# ATmega329P device description
Architecture: AVR8; Family: megaAVR
Registers are 8-bit, access not given, no defined reset value unless marked. A register's access mark holds for its fields unless they carry their own. Offsets are from the block's base; [hi:lo] are bit positions; {n}, {i} and the like mark numbered series.

## USI — Universal Serial Interface
Instances: USI 0x00
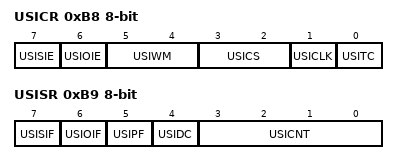
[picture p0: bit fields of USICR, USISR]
0xB8 USICR — USI Control Register
  [7] USISIE — Start Condition Interrupt Enable
  [6] USIOIE — Counter Overflow Interrupt Enable
  [5:4] USIWM — USI Wire Mode Bits
    0=Normal Operation; 1=Three-Wire Mode; 2=Two-Wire Mode; 3=Two-Wire Mode Held Low
  [3:2] USICS — USI Clock Source Select Bits
  [1] USICLK — Clock Strobe
  [0] USITC — Toggle Clock Port Pin
0xB9 USISR — USI Status Register
  [7] USISIF — Start Condition Interrupt Flag
  [6] USIOIF — Counter Overflow Interrupt Flag
  [5] USIPF — Stop Condition Flag
  [4] USIDC — Data Output Collision
  [3:0] USICNT — USI Counter Value Bits
0xBA USIDR — USI Data Register

## ADC — Analog-to-Digital Converter
Instances: ADC 0x00
0x78 ADC 16-bit — ADC Data Register Bytes
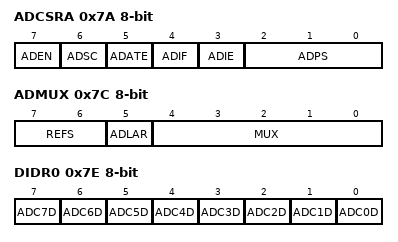
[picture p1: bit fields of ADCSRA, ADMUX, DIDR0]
0x7A ADCSRA — The ADC Control and Status register
  [7] ADEN — ADC Enable
  [6] ADSC — ADC Start Conversion
  [5] ADATE — ADC Auto Trigger Enable
  [4] ADIF — ADC Interrupt Flag
  [3] ADIE — ADC Interrupt Enable
  [2:0] ADPS — ADC Prescaler Select Bits
    0=2; 1=2; 2=4; 3=8; 4=16; 5=32; 6=64; 7=128
0x7B ADCSRB — ADC Control and Status Register B
  [2:0] ADTS — ADC Auto Trigger Sources
0x7C ADMUX — The ADC multiplexer Selection Register
  [7:6] REFS — Reference Selection Bits
    0=AREF, Internal Vref turned off; 1=AVCC with external capacitor at AREF pin; 3=Internal 1.1V Voltage Reference with external capacitor at AREF pin
  [5] ADLAR — Left Adjust Result
  [4:0] MUX — Analog Channel and Gain Selection Bits
0x7E DIDR0 — Digital Input Disable Register 0
  [n] ADC{n}D (n=0..7) — ADC{n} Digital input Disable

## BOOT_LOAD — Bootloader
Instances: BOOT_LOAD 0x00
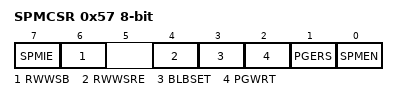
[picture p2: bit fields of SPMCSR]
0x57 SPMCSR — Store Program Memory Control Register
  [7] SPMIE — SPM Interrupt Enable
  [6] RWWSB — Read While Write Section Busy
  [4] RWWSRE — Read While Write section read enable
  [3] BLBSET — Boot Lock Bit Set
  [2] PGWRT — Page Write
  [1] PGERS — Page Erase
  [0] SPMEN — Store Program Memory Enable

## USART0 — USART
Instances: USART0 0x00
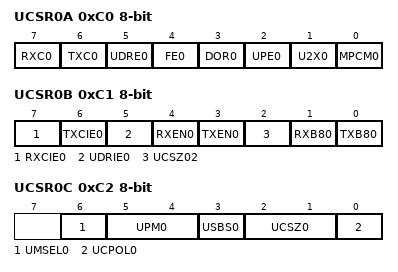
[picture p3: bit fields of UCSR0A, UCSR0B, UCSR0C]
0xC0 UCSR0A — USART Control and Status Register A
  [7] RXC0 — USART Receive Complete
  [6] TXC0 — USART Transmit Complete
  [5] UDRE0 — USART Data Register Empty
  [4] FE0 — Framing Error
  [3] DOR0 — Data OverRun
  [2] UPE0 — USART Parity Error
  [1] U2X0 — Double the USART Transmission Speed
  [0] MPCM0 — Multi-processor Communication Mode
0xC1 UCSR0B — USART Control and Status Register B
  [7] RXCIE0 — RX Complete Interrupt Enable
  [6] TXCIE0 — TX Complete Interrupt Enable
  [5] UDRIE0 — USART Data Register Empty Interrupt Enable
  [4] RXEN0 — Receiver Enable
  [3] TXEN0 — Transmitter Enable
  [2] UCSZ02 — Character Size
  [1] RXB80 — Receive Data Bit 8
  [0] TXB80 — Transmit Data Bit 8
0xC2 UCSR0C — USART Control and Status Register C
  [6] UMSEL0 — USART Mode Select
    0=Asynchronous Operation; 1=Synchronous Operation
  [5:4] UPM0 — Parity Mode Bits
    0=Disabled; 2=Enabled, Even Parity; 3=Enabled, Odd Parity
  [3] USBS0 — Stop Bit Select
    0=1-bit; 1=2-bit
  [2:1] UCSZ0 — Character Size
  [0] UCPOL0 — Clock Polarity
0xC4 UBRR0 16-bit bits used 11:0 — USART Baud Rate Register Bytes
0xC6 UDR0 — USART I/O Data Register

## LCD — Liquid Crystal Display
Instances: LCD 0x00
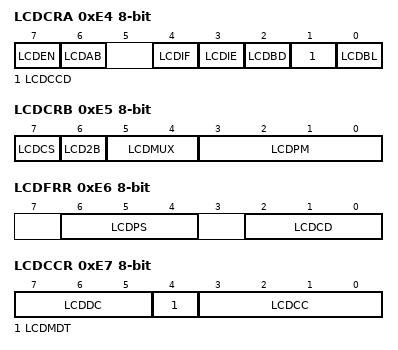
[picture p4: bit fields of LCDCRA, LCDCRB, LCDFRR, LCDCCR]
0xE4 LCDCRA — LCD Control Register A
  [7] LCDEN — LCD Enable
  [6] LCDAB — LCD A or B waveform
  [4] LCDIF — LCD Interrupt Flag
  [3] LCDIE — LCD Interrupt Enable
  [2] LCDBD — LCD Buffer Disable
  [1] LCDCCD — LCD Contrast Control Disable
  [0] LCDBL — LCD Blanking
0xE5 LCDCRB — LCD Control and Status Register B
  [7] LCDCS — LCD CLock Select
  [6] LCD2B — LCD 1/2 Bias Select
  [5:4] LCDMUX — LCD Mux Selects
  [3:0] LCDPM — LCD Port Masks
    0=SEG0:12; 1=SEG0:14; 2=SEG0:15; 3=SEG0:18; 4=SEG0:20; 5=SEG0:22; 6=SEG0:23; 7=SEG0:24; 8=SEG0:26; 9=SEG0:28; 10=SEG0:30; 11=SEG0:32; 12=SEG0:34; 13=SEG0:36; 14=SEG0:38; 15=SEG0:39
0xE6 LCDFRR — LCD Frame Rate Register
  [6:4] LCDPS — LCD Prescaler Selects
    0=ClkLCD/16; 1=ClkLCD/64; 2=ClkLCD/128; 3=ClkLCD/256; 4=ClkLCD/512; 5=ClkLCD/1024; 6=ClkLCD/2048; 7=ClkLCD/4096
  [2:0] LCDCD — LCD Clock Dividers
    {v}={v+1} (v=0..7)
0xE7 LCDCCR — LCD Contrast Control Register
  [7:5] LCDDC
    0=300us; 1=70us; 2=150us; 3=450us; 4=575us; 5=850us; 6=1150us; 7=50% of LCD clock
  [4] LCDMDT — LCD Maximum Drive Time
  [3:0] LCDCC — LCD Contrast Controls
    0=2.60V; 1=2.65V; 2=2.70V; 3=2.75V; 4=2.80V; 5=2.85V; 6=2.90V; 7=2.95V; 8=3.00V; 9=3.05V; 10=3.10V; 11=3.15V; 12=3.20V; 13=3.25V; 14=3.30V; 15=3.35V
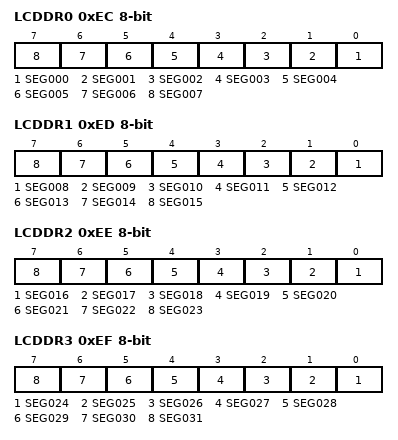
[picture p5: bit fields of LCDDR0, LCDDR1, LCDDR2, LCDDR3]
0xEC LCDDR0 — LCD Data Register 0
  [n] SEG{n:03} (n=0..7) — LCD memory bit segment
0xED LCDDR1 — LCD Data Register 1
  [n-8] SEG{n:03} (n=8..15) — LCD memory bit segment
0xEE LCDDR2 — LCD Data Register 2
  [n-16] SEG{n:03} (n=16..23) — LCD memory bit segment
0xEF LCDDR3 — LCD Data Register 3
  [n-24] SEG{n:03} (n=24..31) — LCD memory bit segment
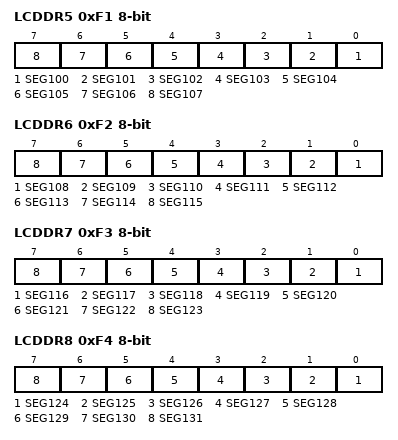
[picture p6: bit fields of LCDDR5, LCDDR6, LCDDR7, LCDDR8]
0xF1 LCDDR5 — LCD Data Register 5
  [n-100] SEG{n} (n=100..107) — LCD memory bit segment
0xF2 LCDDR6 — LCD Data Register 6
  [n-108] SEG{n} (n=108..115) — LCD memory bit segment
0xF3 LCDDR7 — LCD Data Register 7
  [n-116] SEG{n} (n=116..123) — LCD memory bit segment
0xF4 LCDDR8 — LCD Data Register 8
  [n-124] SEG{n} (n=124..131) — LCD memory bit segment
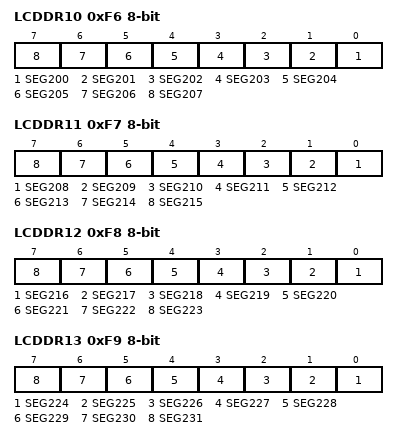
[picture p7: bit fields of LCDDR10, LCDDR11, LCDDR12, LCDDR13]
0xF6 LCDDR10 — LCD Data Register 10
  [n-200] SEG{n} (n=200..207) — LCD memory bit segment
0xF7 LCDDR11 — LCD Data Register 11
  [n-208] SEG{n} (n=208..215) — LCD memory bit segment
0xF8 LCDDR12 — LCD Data Register 12
  [n-216] SEG{n} (n=216..223) — LCD memory bit segment
0xF9 LCDDR13 — LCD Data Register 13
  [n-224] SEG{n} (n=224..231) — LCD memory bit segment
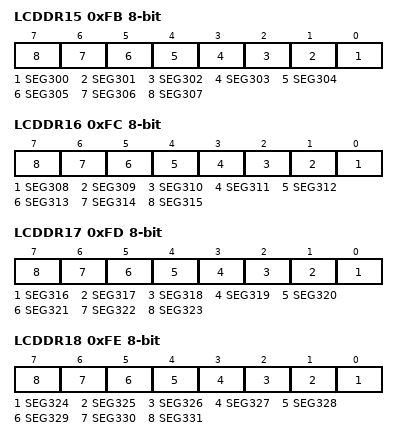
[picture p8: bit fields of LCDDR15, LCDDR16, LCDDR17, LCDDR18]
0xFB LCDDR15 — LCD Data Register 15
  [n-300] SEG{n} (n=300..307) — LCD memory bit segment
0xFC LCDDR16 — LCD Data Register 16
  [n-308] SEG{n} (n=308..315) — LCD memory bit segment
0xFD LCDDR17 — LCD Data Register 17
  [n-316] SEG{n} (n=316..323) — LCD memory bit segment
0xFE LCDDR18 — LCD Data Register 18
  [n-324] SEG{n} (n=324..331) — LCD memory bit segment

## CPU — CPU Registers
Instances: CPU 0x00
Parameters: CORE_VERSION=V2E
0x3E GPIOR0 — General Purpose IO Register 0
0x4A GPIOR1 — General Purpose IO Register 1
0x4B GPIOR2 — General Purpose IO Register 2
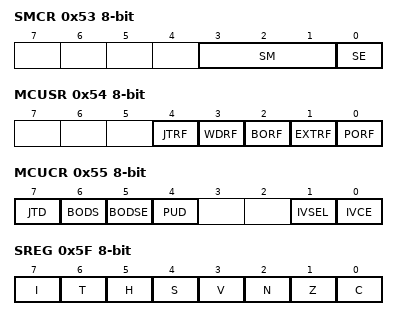
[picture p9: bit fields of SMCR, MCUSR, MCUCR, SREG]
0x53 SMCR — Sleep Mode Control Register
  [3:1] SM — Sleep Mode Select bits
    0=IDLE; 1=ADC (ADC Noise Reduction (If Available)); 2=PDOWN (Power Down); 3=PSAVE (Power Save); 6=STDBY (Standby)
  [0] SE — Sleep Enable
0x54 MCUSR — MCU Status Register
  [4] JTRF — JTAG Reset Flag
  [3] WDRF — Watchdog Reset Flag
  [2] BORF — Brown-out Reset Flag
  [1] EXTRF — External Reset Flag
  [0] PORF — Power-on reset flag
0x55 MCUCR — MCU Control Register
  [7] JTD — JTAG Interface Disable
  [6] BODS — BOD Sleep
  [5] BODSE — BOD Sleep Enable
  [4] PUD — Pull-up disable
  [1] IVSEL — Interrupt Vector Select
  [0] IVCE — Interrupt Vector Change Enable
0x5D SP 16-bit — Stack Pointer
0x5F SREG — Status Register
  [7] I — Global Interrupt Enable
  [6] T — Bit Copy Storage
  [5] H — Half Carry Flag
  [4] S — Sign Bit
  [3] V — Two's Complement Overflow Flag
  [2] N — Negative Flag
  [1] Z — Zero Flag
  [0] C — Carry Flag
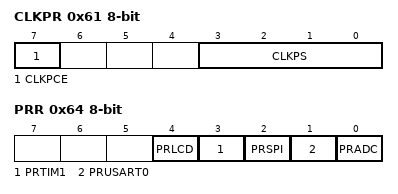
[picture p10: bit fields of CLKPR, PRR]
0x61 CLKPR — Clock Prescale Register
  [7] CLKPCE — Clock Prescaler Change Enable
  [3:0] CLKPS — Clock Prescaler Select Bits
    0=1; 1=2; 2=4; 3=8; 4=16; 5=32; 6=64; 7=128; 8=256
0x64 PRR — Power Reduction Register
  [4] PRLCD — Power Reduction LCD
  [3] PRTIM1 — Power Reduction Timer/Counter1
  [2] PRSPI — Power Reduction Serial Peripheral Interface
  [1] PRUSART0 — Power Reduction USART
  [0] PRADC — Power Reduction ADC
0x66 OSCCAL — Oscillator Calibration Value
  [7:0] OSCCAL — Oscillator Calibration
Value list OSCCAL_VALUE_ADDRESSES: 0=8_0_MHz
